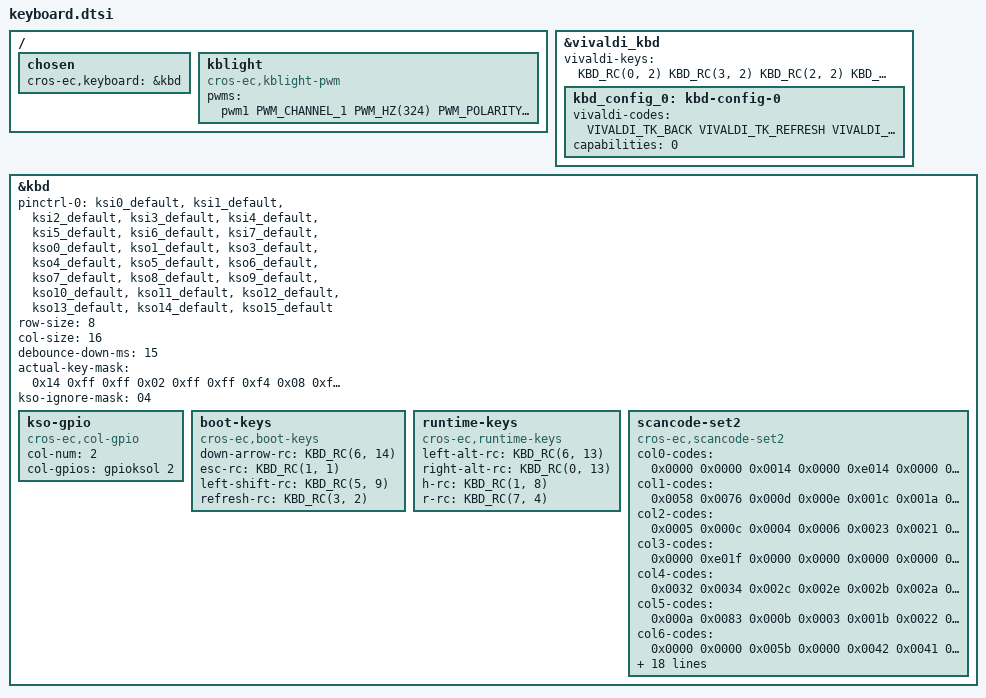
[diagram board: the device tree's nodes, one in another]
/* Copyright 2024 The ChromiumOS Authors
 * Use of this source code is governed by a BSD-style license that can be
 * found in the LICENSE file.
 */

/ {
	chosen {
		cros-ec,keyboard = &kbd;
	};

	kblight: kblight {
		compatible = "cros-ec,kblight-pwm";
		pwms = <&pwm1 PWM_CHANNEL_1 PWM_HZ(324) PWM_POLARITY_NORMAL>;
	};
};

&vivaldi_kbd {
	vivaldi-keys = <
	       KBD_RC(0, 2)  /* T1 */
	       KBD_RC(3, 2)  /* T2 */
	       KBD_RC(2, 2)  /* T3 */
	       KBD_RC(1, 2)  /* T4 */
	       KBD_RC(3, 5)  /* T5 */
	       KBD_RC(2, 5)  /* T6 */
	       KBD_RC(1, 5)  /* T7 */
	       KBD_RC(0, 5)  /* T8 */
	       KBD_RC(3, 11)  /* T9 */
	       KBD_RC(2, 11)  /* T10 */
	       KBD_RC(1, 11)  /* T11 */
	       KBD_RC(0, 11)  /* T12 */
	>;

	kbd_config_0: kbd-config-0 {
		vivaldi-codes = <
			VIVALDI_TK_BACK               /* T1 */
			VIVALDI_TK_REFRESH            /* T2 */
			VIVALDI_TK_FULLSCREEN         /* T3 */
			VIVALDI_TK_KBD_BKLIGHT_TOGGLE /* T4 */
			VIVALDI_TK_VOL_MUTE           /* T5 */
			VIVALDI_TK_VOL_DOWN           /* T6 */
			VIVALDI_TK_VOL_UP             /* T7 */
			VIVALDI_TK_MICMUTE            /* T8 */
			VIVALDI_TK_PREV_TRACK         /* T9 */
			VIVALDI_TK_PLAY_PAUSE         /* T10 */
			VIVALDI_TK_BRIGHTNESS_DOWN    /* T11 */
			VIVALDI_TK_BRIGHTNESS_UP      /* T12 */
		>;
		capabilities = <0>;                  /* No lock button */
	};
};

&kbd {
	status = "okay";
	pinctrl-0 = <
		&ksi0_default
		&ksi1_default
		&ksi2_default
		&ksi3_default
		&ksi4_default
		&ksi5_default
		&ksi6_default
		&ksi7_default
		&kso0_default
		&kso1_default
		&kso3_default
		&kso4_default
		&kso5_default
		&kso6_default
		&kso7_default
		&kso8_default
		&kso9_default
		&kso10_default
		&kso11_default
		&kso12_default
		&kso13_default
		&kso14_default
		&kso15_default
	>;
	pinctrl-names = "default";
	row-size = <8>;
	col-size = <16>;
	debounce-down-ms = <15>;
	actual-key-mask = <0x14 0xff 0xff 0x02 0xff 0xff 0xf4 0x08
			   0xff 0xa0 0xff 0xff 0xff 0x41 0xfa 0xff>;
	kso-ignore-mask = <04>;

	kso-gpio {
		compatible = "cros-ec,col-gpio";
		col-num = <2>;
		col-gpios = <&gpioksol 2 GPIO_ACTIVE_HIGH>;
	};

	boot-keys {
		compatible = "cros-ec,boot-keys";
		down-arrow-rc = <KBD_RC(6, 14)>;
		esc-rc = <KBD_RC(1, 1)>;
		left-shift-rc = <KBD_RC(5, 9)>;
		refresh-rc = <KBD_RC(3, 2)>;
	};

	runtime-keys {
		compatible = "cros-ec,runtime-keys";
		left-alt-rc = <KBD_RC(6, 13)>;
		right-alt-rc = <KBD_RC(0, 13)>;
		h-rc = <KBD_RC(1, 8)>;
		r-rc = <KBD_RC(7, 4)>;
	};
	scancode-set2 {
		compatible = "cros-ec,scancode-set2";
		col0-codes  = <0x0000 0x0000 0x0014 0x0000 0xe014 0x0000 0x0000 0x0000>;
		col1-codes  = <0x0058 0x0076 0x000d 0x000e 0x001c 0x001a 0x0016 0x0015>;
		col2-codes  = <0x0005 0x000c 0x0004 0x0006 0x0023 0x0021 0x0026 0x0024>;
		col3-codes  = <0x0000 0xe01f 0x0000 0x0000 0x0000 0x0000 0x0000 0x0000>;
		col4-codes  = <0x0032 0x0034 0x002c 0x002e 0x002b 0x002a 0x0025 0x002d>;
		col5-codes  = <0x000a 0x0083 0x000b 0x0003 0x001b 0x0022 0x001e 0x001d>;
		col6-codes  = <0x0000 0x0000 0x005b 0x0000 0x0042 0x0041 0x003e 0x0043>;
		col7-codes  = <0x0000 0x0000 0x0000 0xe01f 0x0000 0x0000 0x0000 0x0000>;
		col8-codes  = <0x0031 0x0033 0x0035 0x0036 0x003b 0x003a 0x003d 0x003c>;
		col9-codes  = <0x0000 0x0000 0x0000 0x0000 0x0000 0x0012 0x0000 0x0059>;
		col10-codes = <0x0055 0x0052 0x0054 0x004e 0x004c 0x004a 0x0045 0x004d>;
		col11-codes = <0x0007 0x0078 0x0009 0x0001 0x004b 0x0049 0x0046 0x0044>;
		col12-codes = <0x0000 0x0000 0x0000 0x0000 0x0000 0x0000 0x0000 0x0000>;
		col13-codes = <0xe011 0x0000 0x0000 0x0000 0x0000 0x0000 0x0011 0x0000>;
		col14-codes = <0x0000 0x0066 0x0000 0x005d 0x005a 0x0029 0xe072 0xe075>;
		col15-codes = <0xe071 0xe07c 0xe06c 0xe07d 0xe07a 0xe069 0xe074 0xe06b>;
	};
};
